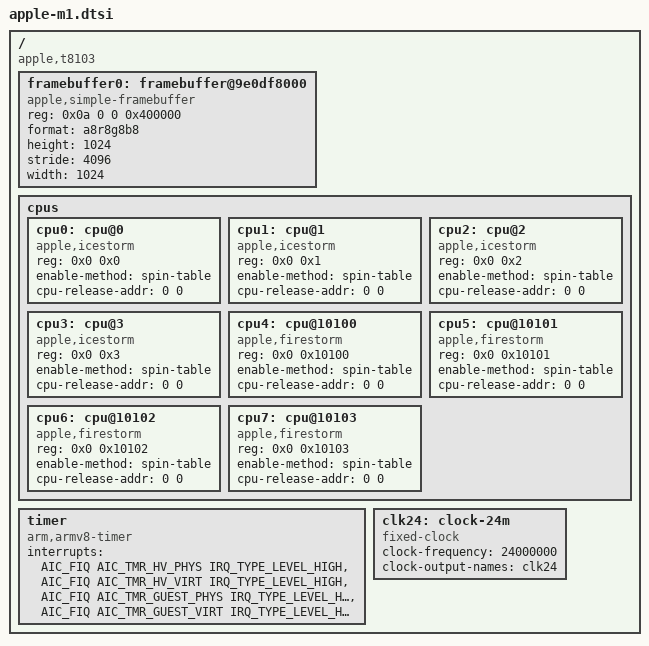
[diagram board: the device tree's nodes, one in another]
// SPDX-License-Identifier: GPL-2.0+ OR MIT
/*
 * Apple T8103 "M1" SoC
 *
 * Other names: H13G, "Tonga"
 *
 * Copyright The Asahi Linux Contributors
 */

#include <dt-bindings/interrupt-controller/apple-aic.h>
#include <dt-bindings/interrupt-controller/irq.h>
#include <dt-bindings/pinctrl/apple.h>
#include <dt-bindings/spmi/spmi.h>

/ {
	compatible = "apple,t8103", "apple,arm-platform";

	#address-cells = <2>;
	#size-cells = <2>;

	framebuffer0: framebuffer@9e0df8000 {
		compatible = "apple,simple-framebuffer", "simple-framebuffer";
		reg = <0x0a 0 0 0x400000>;
		format = "a8r8g8b8";
		height = <1024>;
		stride = <4096>;
		width = <1024>;
		status = "okay";
	};
	cpus {
		#address-cells = <2>;
		#size-cells = <0>;

		cpu0: cpu@0 {
			compatible = "apple,icestorm";
			device_type = "cpu";
			reg = <0x0 0x0>;
			enable-method = "spin-table";
			cpu-release-addr = <0 0>; /* To be filled by loader */
		};

		cpu1: cpu@1 {
			compatible = "apple,icestorm";
			device_type = "cpu";
			reg = <0x0 0x1>;
			enable-method = "spin-table";
			cpu-release-addr = <0 0>; /* To be filled by loader */
		};

		cpu2: cpu@2 {
			compatible = "apple,icestorm";
			device_type = "cpu";
			reg = <0x0 0x2>;
			enable-method = "spin-table";
			cpu-release-addr = <0 0>; /* To be filled by loader */
		};

		cpu3: cpu@3 {
			compatible = "apple,icestorm";
			device_type = "cpu";
			reg = <0x0 0x3>;
			enable-method = "spin-table";
			cpu-release-addr = <0 0>; /* To be filled by loader */
		};

		cpu4: cpu@10100 {
			compatible = "apple,firestorm";
			device_type = "cpu";
			reg = <0x0 0x10100>;
			enable-method = "spin-table";
			cpu-release-addr = <0 0>; /* To be filled by loader */
		};

		cpu5: cpu@10101 {
			compatible = "apple,firestorm";
			device_type = "cpu";
			reg = <0x0 0x10101>;
			enable-method = "spin-table";
			cpu-release-addr = <0 0>; /* To be filled by loader */
		};

		cpu6: cpu@10102 {
			compatible = "apple,firestorm";
			device_type = "cpu";
			reg = <0x0 0x10102>;
			enable-method = "spin-table";
			cpu-release-addr = <0 0>; /* To be filled by loader */
		};

		cpu7: cpu@10103 {
			compatible = "apple,firestorm";
			device_type = "cpu";
			reg = <0x0 0x10103>;
			enable-method = "spin-table";
			cpu-release-addr = <0 0>; /* To be filled by loader */
		};
	};

	timer {
		compatible = "arm,armv8-timer";
		interrupt-names = "hyp-phys", "hyp-virt", "phys", "virt";
		interrupts = <AIC_FIQ AIC_TMR_HV_PHYS IRQ_TYPE_LEVEL_HIGH>,
			     <AIC_FIQ AIC_TMR_HV_VIRT IRQ_TYPE_LEVEL_HIGH>,
			     <AIC_FIQ AIC_TMR_GUEST_PHYS IRQ_TYPE_LEVEL_HIGH>,
			     <AIC_FIQ AIC_TMR_GUEST_VIRT IRQ_TYPE_LEVEL_HIGH>;
	};

	clk24: clock-24m {
		compatible = "fixed-clock";
		#clock-cells = <0>;
		clock-frequency = <24000000>;
		clock-output-names = "clk24";
	};

#if 0
	reserved-memory {
		#address-cells = <0x02>;
		#size-cells = <0x02>;
		ranges;

		fb {
		       reg = <0xa 0x0 0x0 0x400000>;
		       no-map;
		};
	};
#endif
};
